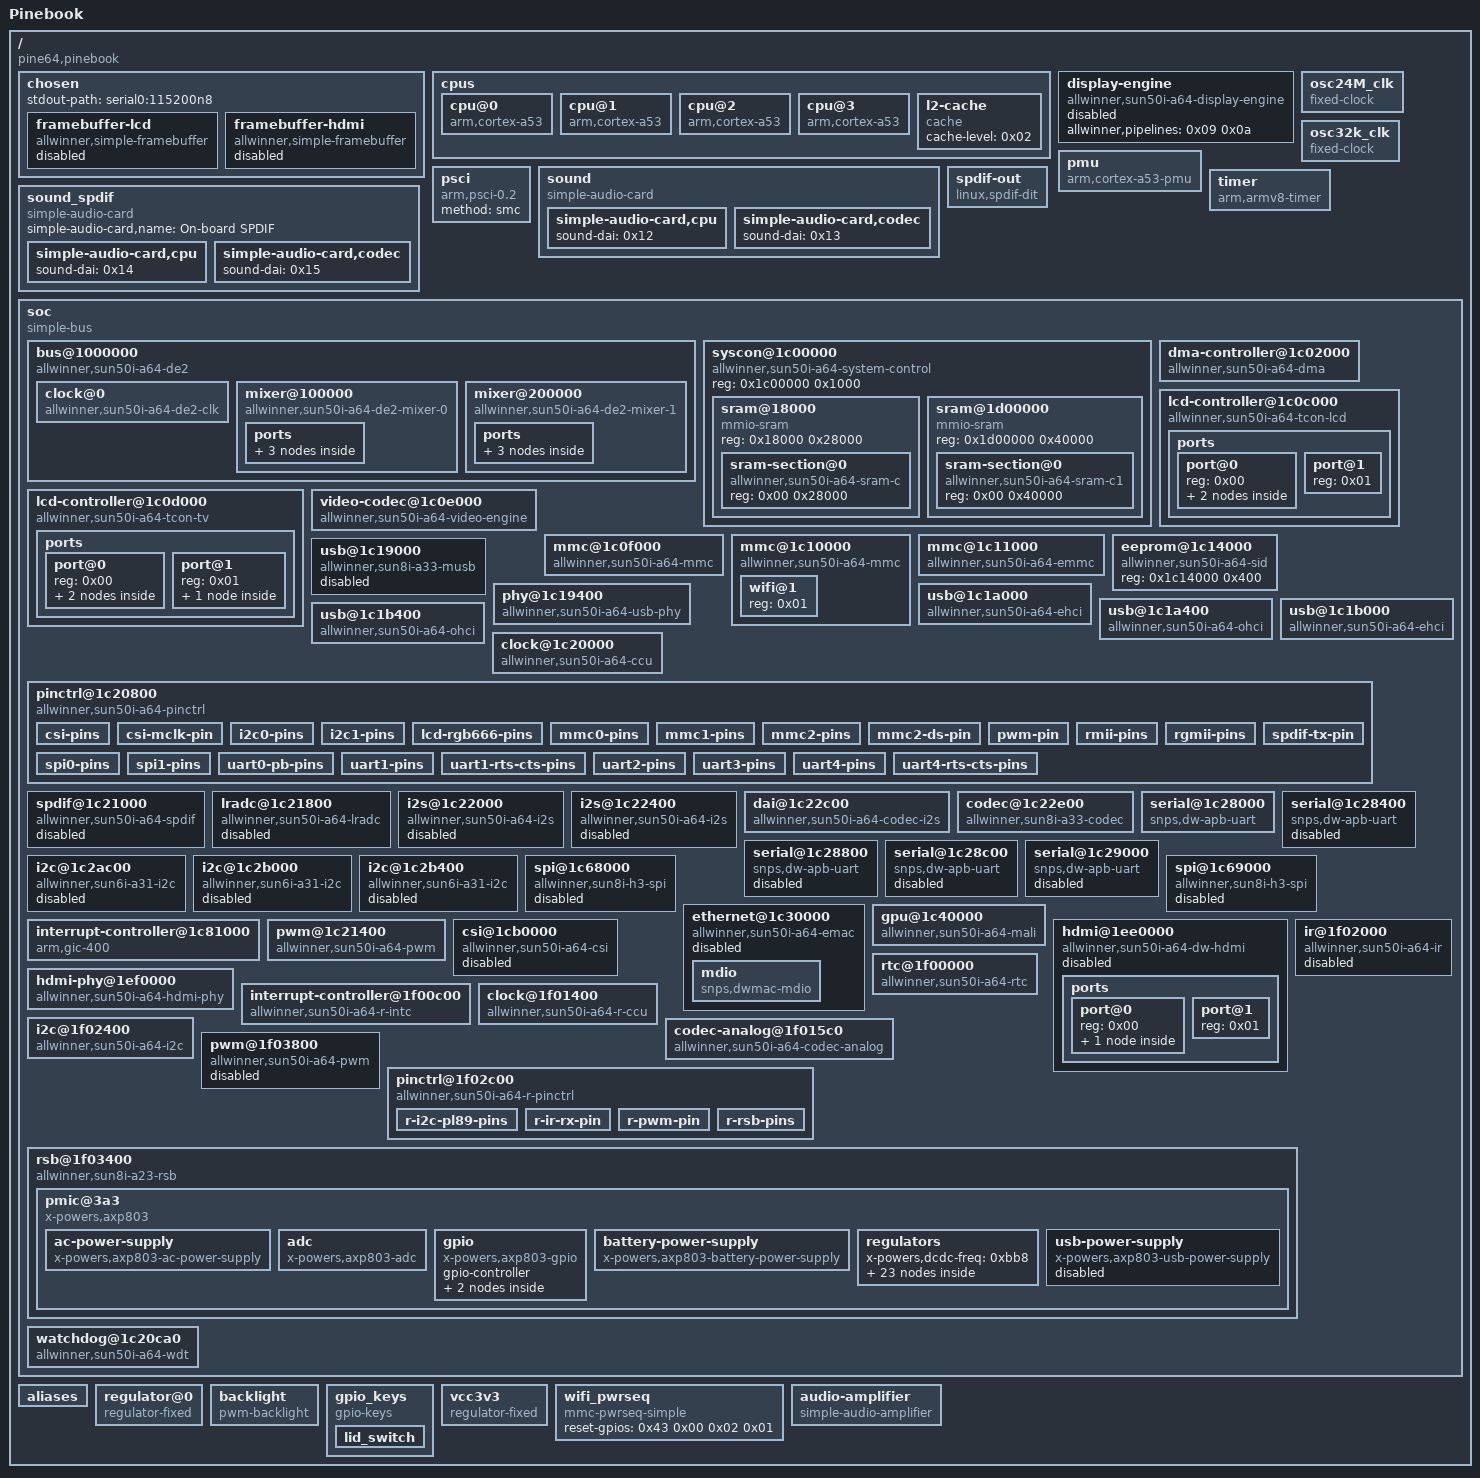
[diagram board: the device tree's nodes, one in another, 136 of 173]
/dts-v1/;

/ {
	interrupt-parent = <0x01>;
	#address-cells = <0x01>;
	#size-cells = <0x01>;
	model = "Pinebook";
	compatible = "pine64,pinebook\0allwinner,sun50i-a64";

	chosen {
		#address-cells = <0x01>;
		#size-cells = <0x01>;
		ranges;
		stdout-path = "serial0:115200n8";

		framebuffer-lcd {
			compatible = "allwinner,simple-framebuffer\0simple-framebuffer";
			allwinner,pipeline = "mixer0-lcd0";
			clocks = <0x02 0x64 0x03 0x06>;
			status = "disabled";
			panel-supply = <0x04>;
			dvdd25-supply = <0x05>;
			dvdd12-supply = <0x06>;
			phandle = <0x44>;
		};

		framebuffer-hdmi {
			compatible = "allwinner,simple-framebuffer\0simple-framebuffer";
			allwinner,pipeline = "mixer1-lcd1-hdmi";
			clocks = <0x03 0x07 0x02 0x65 0x02 0x6e>;
			status = "disabled";
			vcc-hdmi-supply = <0x07>;
			phandle = <0x45>;
		};
	};

	cpus {
		#address-cells = <0x01>;
		#size-cells = <0x00>;

		cpu@0 {
			compatible = "arm,cortex-a53";
			device_type = "cpu";
			reg = <0x00>;
			enable-method = "psci";
			next-level-cache = <0x08>;
			phandle = <0x0b>;
		};

		cpu@1 {
			compatible = "arm,cortex-a53";
			device_type = "cpu";
			reg = <0x01>;
			enable-method = "psci";
			next-level-cache = <0x08>;
			phandle = <0x0c>;
		};

		cpu@2 {
			compatible = "arm,cortex-a53";
			device_type = "cpu";
			reg = <0x02>;
			enable-method = "psci";
			next-level-cache = <0x08>;
			phandle = <0x0d>;
		};

		cpu@3 {
			compatible = "arm,cortex-a53";
			device_type = "cpu";
			reg = <0x03>;
			enable-method = "psci";
			next-level-cache = <0x08>;
			phandle = <0x0e>;
		};

		l2-cache {
			compatible = "cache";
			cache-level = <0x02>;
			phandle = <0x08>;
		};
	};

	display-engine {
		compatible = "allwinner,sun50i-a64-display-engine";
		allwinner,pipelines = <0x09 0x0a>;
		status = "disabled";
		phandle = <0x46>;
	};

	osc24M_clk {
		#clock-cells = <0x00>;
		compatible = "fixed-clock";
		clock-frequency = <0x16e3600>;
		clock-output-names = "osc24M";
		phandle = <0x2c>;
	};

	osc32k_clk {
		#clock-cells = <0x00>;
		compatible = "fixed-clock";
		clock-frequency = <0x8000>;
		clock-output-names = "ext-osc32k";
		phandle = <0x3a>;
	};

	pmu {
		compatible = "arm,cortex-a53-pmu";
		interrupts = <0x00 0x74 0x04 0x00 0x75 0x04 0x00 0x76 0x04 0x00 0x77 0x04>;
		interrupt-affinity = <0x0b 0x0c 0x0d 0x0e>;
	};

	psci {
		compatible = "arm,psci-0.2";
		method = "smc";
	};

	sound {
		compatible = "simple-audio-card";
		simple-audio-card,name = "sun50i-a64-audio";
		simple-audio-card,format = "i2s";
		simple-audio-card,frame-master = <0x0f>;
		simple-audio-card,bitclock-master = <0x0f>;
		simple-audio-card,mclk-fs = <0x80>;
		simple-audio-card,aux-devs = <0x10 0x11>;
		simple-audio-card,routing = "Left DAC\0AIF1 Slot 0 Left\0Right DAC\0AIF1 Slot 0 Right\0Speaker Amp INL\0LINEOUT\0Speaker Amp INR\0LINEOUT\0Internal Speaker\0Speaker Amp OUTL\0Internal Speaker\0Speaker Amp OUTR\0Headphone Jack\0HP\0AIF1 Slot 0 Left ADC\0Left ADC\0AIF1 Slot 0 Right ADC\0Right ADC\0Internal Microphone Left\0MBIAS\0MIC1\0Internal Microphone Left\0Internal Microphone Right\0HBIAS\0MIC2\0Internal Microphone Right";
		status = "okay";
		simple-audio-card,widgets = "Microphone\0Internal Microphone Left\0Microphone\0Internal Microphone Right\0Headphone\0Headphone Jack\0Speaker\0Internal Speaker";
		phandle = <0x47>;

		simple-audio-card,cpu {
			sound-dai = <0x12>;
			phandle = <0x0f>;
		};

		simple-audio-card,codec {
			sound-dai = <0x13>;
			phandle = <0x48>;
		};
	};

	sound_spdif {
		compatible = "simple-audio-card";
		simple-audio-card,name = "On-board SPDIF";

		simple-audio-card,cpu {
			sound-dai = <0x14>;
		};

		simple-audio-card,codec {
			sound-dai = <0x15>;
		};
	};

	spdif-out {
		#sound-dai-cells = <0x00>;
		compatible = "linux,spdif-dit";
		phandle = <0x15>;
	};

	timer {
		compatible = "arm,armv8-timer";
		allwinner,erratum-unknown1;
		interrupts = <0x01 0x0d 0xf04 0x01 0x0e 0xf04 0x01 0x0b 0xf04 0x01 0x0a 0xf04>;
	};

	soc {
		compatible = "simple-bus";
		#address-cells = <0x01>;
		#size-cells = <0x01>;
		ranges;

		bus@1000000 {
			compatible = "allwinner,sun50i-a64-de2";
			reg = <0x1000000 0x400000>;
			allwinner,sram = <0x16 0x01>;
			#address-cells = <0x01>;
			#size-cells = <0x01>;
			ranges = <0x00 0x1000000 0x400000>;

			clock@0 {
				compatible = "allwinner,sun50i-a64-de2-clk";
				reg = <0x00 0x10000>;
				clocks = <0x02 0x34 0x02 0x63>;
				clock-names = "bus\0mod";
				resets = <0x02 0x1e>;
				#clock-cells = <0x01>;
				#reset-cells = <0x01>;
				phandle = <0x03>;
			};

			mixer@100000 {
				compatible = "allwinner,sun50i-a64-de2-mixer-0";
				reg = <0x100000 0x100000>;
				clocks = <0x03 0x00 0x03 0x06>;
				clock-names = "bus\0mod";
				resets = <0x03 0x00>;
				phandle = <0x09>;

				ports {
					#address-cells = <0x01>;
					#size-cells = <0x00>;

					port@1 {
						#address-cells = <0x01>;
						#size-cells = <0x00>;
						reg = <0x01>;
						phandle = <0x49>;

						endpoint@0 {
							reg = <0x00>;
							remote-endpoint = <0x17>;
							phandle = <0x1b>;
						};

						endpoint@1 {
							reg = <0x01>;
							remote-endpoint = <0x18>;
							phandle = <0x1d>;
						};
					};
				};
			};

			mixer@200000 {
				compatible = "allwinner,sun50i-a64-de2-mixer-1";
				reg = <0x200000 0x100000>;
				clocks = <0x03 0x01 0x03 0x07>;
				clock-names = "bus\0mod";
				resets = <0x03 0x01>;
				phandle = <0x0a>;

				ports {
					#address-cells = <0x01>;
					#size-cells = <0x00>;

					port@1 {
						#address-cells = <0x01>;
						#size-cells = <0x00>;
						reg = <0x01>;
						phandle = <0x4a>;

						endpoint@0 {
							reg = <0x00>;
							remote-endpoint = <0x19>;
							phandle = <0x1c>;
						};

						endpoint@1 {
							reg = <0x01>;
							remote-endpoint = <0x1a>;
							phandle = <0x1e>;
						};
					};
				};
			};
		};

		syscon@1c00000 {
			compatible = "allwinner,sun50i-a64-system-control";
			reg = <0x1c00000 0x1000>;
			#address-cells = <0x01>;
			#size-cells = <0x01>;
			ranges;
			phandle = <0x35>;

			sram@18000 {
				compatible = "mmio-sram";
				reg = <0x18000 0x28000>;
				#address-cells = <0x01>;
				#size-cells = <0x01>;
				ranges = <0x00 0x18000 0x28000>;
				phandle = <0x4b>;

				sram-section@0 {
					compatible = "allwinner,sun50i-a64-sram-c";
					reg = <0x00 0x28000>;
					phandle = <0x16>;
				};
			};

			sram@1d00000 {
				compatible = "mmio-sram";
				reg = <0x1d00000 0x40000>;
				#address-cells = <0x01>;
				#size-cells = <0x01>;
				ranges = <0x00 0x1d00000 0x40000>;
				phandle = <0x4c>;

				sram-section@0 {
					compatible = "allwinner,sun50i-a64-sram-c1\0allwinner,sun4i-a10-sram-c1";
					reg = <0x00 0x40000>;
					phandle = <0x20>;
				};
			};
		};

		dma-controller@1c02000 {
			compatible = "allwinner,sun50i-a64-dma";
			reg = <0x1c02000 0x1000>;
			interrupts = <0x00 0x32 0x04>;
			clocks = <0x02 0x1e>;
			dma-channels = <0x08>;
			dma-requests = <0x1b>;
			resets = <0x02 0x07>;
			#dma-cells = <0x01>;
			phandle = <0x2e>;
		};

		lcd-controller@1c0c000 {
			compatible = "allwinner,sun50i-a64-tcon-lcd\0allwinner,sun8i-a83t-tcon-lcd";
			reg = <0x1c0c000 0x1000>;
			interrupts = <0x00 0x56 0x04>;
			clocks = <0x02 0x2f 0x02 0x64>;
			clock-names = "ahb\0tcon-ch0";
			clock-output-names = "tcon-pixel-clock";
			#clock-cells = <0x00>;
			resets = <0x02 0x18 0x02 0x23>;
			reset-names = "lcd\0lvds";
			phandle = <0x4d>;

			ports {
				#address-cells = <0x01>;
				#size-cells = <0x00>;

				port@0 {
					#address-cells = <0x01>;
					#size-cells = <0x00>;
					reg = <0x00>;
					phandle = <0x4e>;

					endpoint@0 {
						reg = <0x00>;
						remote-endpoint = <0x1b>;
						phandle = <0x17>;
					};

					endpoint@1 {
						reg = <0x01>;
						remote-endpoint = <0x1c>;
						phandle = <0x19>;
					};
				};

				port@1 {
					#address-cells = <0x01>;
					#size-cells = <0x00>;
					reg = <0x01>;
					phandle = <0x4f>;
				};
			};
		};

		lcd-controller@1c0d000 {
			compatible = "allwinner,sun50i-a64-tcon-tv\0allwinner,sun8i-a83t-tcon-tv";
			reg = <0x1c0d000 0x1000>;
			interrupts = <0x00 0x57 0x04>;
			clocks = <0x02 0x30 0x02 0x65>;
			clock-names = "ahb\0tcon-ch1";
			resets = <0x02 0x19>;
			reset-names = "lcd";
			phandle = <0x50>;

			ports {
				#address-cells = <0x01>;
				#size-cells = <0x00>;

				port@0 {
					#address-cells = <0x01>;
					#size-cells = <0x00>;
					reg = <0x00>;
					phandle = <0x51>;

					endpoint@0 {
						reg = <0x00>;
						remote-endpoint = <0x1d>;
						phandle = <0x18>;
					};

					endpoint@1 {
						reg = <0x01>;
						remote-endpoint = <0x1e>;
						phandle = <0x1a>;
					};
				};

				port@1 {
					#address-cells = <0x01>;
					#size-cells = <0x00>;
					reg = <0x01>;
					phandle = <0x52>;

					endpoint@1 {
						reg = <0x01>;
						remote-endpoint = <0x1f>;
						phandle = <0x39>;
					};
				};
			};
		};

		video-codec@1c0e000 {
			compatible = "allwinner,sun50i-a64-video-engine";
			reg = <0x1c0e000 0x1000>;
			clocks = <0x02 0x2e 0x02 0x6a 0x02 0x5f>;
			clock-names = "ahb\0mod\0ram";
			resets = <0x02 0x17>;
			interrupts = <0x00 0x3a 0x04>;
			allwinner,sram = <0x20 0x01>;
		};

		mmc@1c0f000 {
			compatible = "allwinner,sun50i-a64-mmc";
			reg = <0x1c0f000 0x1000>;
			clocks = <0x02 0x1f 0x02 0x4b>;
			clock-names = "ahb\0mmc";
			resets = <0x02 0x08>;
			reset-names = "ahb";
			interrupts = <0x00 0x3c 0x04>;
			max-frequency = <0x8f0d180>;
			status = "okay";
			#address-cells = <0x01>;
			#size-cells = <0x00>;
			pinctrl-names = "default";
			pinctrl-0 = <0x21>;
			vmmc-supply = <0x22>;
			cd-gpios = <0x23 0x05 0x06 0x01>;
			disable-wp;
			bus-width = <0x04>;
			phandle = <0x53>;
		};

		mmc@1c10000 {
			compatible = "allwinner,sun50i-a64-mmc";
			reg = <0x1c10000 0x1000>;
			clocks = <0x02 0x20 0x02 0x4c>;
			clock-names = "ahb\0mmc";
			resets = <0x02 0x09>;
			reset-names = "ahb";
			interrupts = <0x00 0x3d 0x04>;
			max-frequency = <0x8f0d180>;
			status = "okay";
			#address-cells = <0x01>;
			#size-cells = <0x00>;
			pinctrl-names = "default";
			pinctrl-0 = <0x24>;
			vmmc-supply = <0x25>;
			vqmmc-supply = <0x26>;
			mmc-pwrseq = <0x27>;
			bus-width = <0x04>;
			non-removable;
			phandle = <0x54>;

			wifi@1 {
				reg = <0x01>;
				phandle = <0x55>;
			};
		};

		mmc@1c11000 {
			compatible = "allwinner,sun50i-a64-emmc";
			reg = <0x1c11000 0x1000>;
			clocks = <0x02 0x21 0x02 0x4d>;
			clock-names = "ahb\0mmc";
			resets = <0x02 0x0a>;
			reset-names = "ahb";
			interrupts = <0x00 0x3e 0x04>;
			max-frequency = <0xbebc200>;
			status = "okay";
			#address-cells = <0x01>;
			#size-cells = <0x00>;
			pinctrl-names = "default";
			pinctrl-0 = <0x28 0x29>;
			vmmc-supply = <0x22>;
			vqmmc-supply = <0x26>;
			bus-width = <0x08>;
			non-removable;
			cap-mmc-hw-reset;
			mmc-hs200-1_8v;
			phandle = <0x56>;
		};

		eeprom@1c14000 {
			compatible = "allwinner,sun50i-a64-sid";
			reg = <0x1c14000 0x400>;
			phandle = <0x57>;
		};

		usb@1c19000 {
			compatible = "allwinner,sun8i-a33-musb";
			reg = <0x1c19000 0x400>;
			clocks = <0x02 0x29>;
			resets = <0x02 0x12>;
			interrupts = <0x00 0x47 0x04>;
			interrupt-names = "mc";
			phys = <0x2a 0x00>;
			phy-names = "usb";
			extcon = <0x2a 0x00>;
			dr_mode = "host";
			status = "disabled";
			phandle = <0x58>;
		};

		phy@1c19400 {
			compatible = "allwinner,sun50i-a64-usb-phy";
			reg = <0x1c19400 0x14 0x1c1a800 0x04 0x1c1b800 0x04>;
			reg-names = "phy_ctrl\0pmu0\0pmu1";
			clocks = <0x02 0x56 0x02 0x57>;
			clock-names = "usb0_phy\0usb1_phy";
			resets = <0x02 0x00 0x02 0x01>;
			reset-names = "usb0_reset\0usb1_reset";
			status = "okay";
			#phy-cells = <0x01>;
			usb0_vbus-supply = <0x2b>;
			usb1_vbus-supply = <0x2b>;
			phandle = <0x2a>;
		};

		usb@1c1a000 {
			compatible = "allwinner,sun50i-a64-ehci\0generic-ehci";
			reg = <0x1c1a000 0x100>;
			interrupts = <0x00 0x48 0x04>;
			clocks = <0x02 0x2c 0x02 0x2a 0x02 0x5b>;
			resets = <0x02 0x15 0x02 0x13>;
			phys = <0x2a 0x00>;
			phy-names = "usb";
			status = "okay";
			phandle = <0x59>;
		};

		usb@1c1a400 {
			compatible = "allwinner,sun50i-a64-ohci\0generic-ohci";
			reg = <0x1c1a400 0x100>;
			interrupts = <0x00 0x49 0x04>;
			clocks = <0x02 0x2c 0x02 0x5b>;
			resets = <0x02 0x15>;
			phys = <0x2a 0x00>;
			phy-names = "usb";
			status = "okay";
			phandle = <0x5a>;
		};

		usb@1c1b000 {
			compatible = "allwinner,sun50i-a64-ehci\0generic-ehci";
			reg = <0x1c1b000 0x100>;
			interrupts = <0x00 0x4a 0x04>;
			clocks = <0x02 0x2d 0x02 0x2b 0x02 0x5d>;
			resets = <0x02 0x16 0x02 0x14>;
			phys = <0x2a 0x01>;
			phy-names = "usb";
			status = "okay";
			phandle = <0x5b>;
		};

		usb@1c1b400 {
			compatible = "allwinner,sun50i-a64-ohci\0generic-ohci";
			reg = <0x1c1b400 0x100>;
			interrupts = <0x00 0x4b 0x04>;
			clocks = <0x02 0x2d 0x02 0x5d>;
			resets = <0x02 0x16>;
			phys = <0x2a 0x01>;
			phy-names = "usb";
			status = "okay";
			phandle = <0x5c>;
		};

		clock@1c20000 {
			compatible = "allwinner,sun50i-a64-ccu";
			reg = <0x1c20000 0x400>;
			clocks = <0x2c 0x2d 0x00>;
			clock-names = "hosc\0losc";
			#clock-cells = <0x01>;
			#reset-cells = <0x01>;
			phandle = <0x02>;
		};

		pinctrl@1c20800 {
			compatible = "allwinner,sun50i-a64-pinctrl";
			reg = <0x1c20800 0x400>;
			interrupts = <0x00 0x0b 0x04 0x00 0x11 0x04 0x00 0x15 0x04>;
			clocks = <0x02 0x3a 0x2c 0x2d 0x00>;
			clock-names = "apb\0hosc\0losc";
			gpio-controller;
			#gpio-cells = <0x03>;
			interrupt-controller;
			#interrupt-cells = <0x03>;
			phandle = <0x23>;

			csi-pins {
				pins = "PE0\0PE2\0PE3\0PE4\0PE5\0PE6\0PE7\0PE8\0PE9\0PE10\0PE11";
				function = "csi";
				phandle = <0x37>;
			};

			csi-mclk-pin {
				pins = "PE1";
				function = "csi";
				phandle = <0x5d>;
			};

			i2c0-pins {
				pins = "PH0\0PH1";
				function = "i2c0";
				phandle = <0x31>;
			};

			i2c1-pins {
				pins = "PH2\0PH3";
				function = "i2c1";
				phandle = <0x32>;
			};

			lcd-rgb666-pins {
				pins = "PD0\0PD1\0PD2\0PD3\0PD4\0PD5\0PD6\0PD7\0PD8\0PD9\0PD10\0PD11\0PD12\0PD13\0PD14\0PD15\0PD16\0PD17\0PD18\0PD19\0PD20\0PD21";
				function = "lcd0";
				phandle = <0x5e>;
			};

			mmc0-pins {
				pins = "PF0\0PF1\0PF2\0PF3\0PF4\0PF5";
				function = "mmc0";
				drive-strength = <0x1e>;
				bias-pull-up;
				phandle = <0x21>;
			};

			mmc1-pins {
				pins = "PG0\0PG1\0PG2\0PG3\0PG4\0PG5";
				function = "mmc1";
				drive-strength = <0x1e>;
				bias-pull-up;
				phandle = <0x24>;
			};

			mmc2-pins {
				pins = "PC5\0PC6\0PC8\0PC9\0PC10\0PC11\0PC12\0PC13\0PC14\0PC15\0PC16";
				function = "mmc2";
				drive-strength = <0x1e>;
				bias-pull-up;
				phandle = <0x28>;
			};

			mmc2-ds-pin {
				pins = "PC1";
				function = "mmc2";
				drive-strength = <0x1e>;
				bias-pull-up;
				phandle = <0x29>;
			};

			pwm-pin {
				pins = "PD22";
				function = "pwm";
				phandle = <0x36>;
			};

			rmii-pins {
				pins = "PD10\0PD11\0PD13\0PD14\0PD17\0PD18\0PD19\0PD20\0PD22\0PD23";
				function = "emac";
				drive-strength = <0x28>;
				phandle = <0x5f>;
			};

			rgmii-pins {
				pins = "PD8\0PD9\0PD10\0PD11\0PD12\0PD13\0PD15\0PD16\0PD17\0PD18\0PD19\0PD20\0PD21\0PD22\0PD23";
				function = "emac";
				drive-strength = <0x28>;
				phandle = <0x60>;
			};

			spdif-tx-pin {
				pins = "PH8";
				function = "spdif";
				phandle = <0x2f>;
			};

			spi0-pins {
				pins = "PC0\0PC1\0PC2\0PC3";
				function = "spi0";
				phandle = <0x33>;
			};

			spi1-pins {
				pins = "PD0\0PD1\0PD2\0PD3";
				function = "spi1";
				phandle = <0x34>;
			};

			uart0-pb-pins {
				pins = "PB8\0PB9";
				function = "uart0";
				phandle = <0x30>;
			};

			uart1-pins {
				pins = "PG6\0PG7";
				function = "uart1";
				phandle = <0x61>;
			};

			uart1-rts-cts-pins {
				pins = "PG8\0PG9";
				function = "uart1";
				phandle = <0x62>;
			};

			uart2-pins {
				pins = "PB0\0PB1";
				function = "uart2";
				phandle = <0x63>;
			};

			uart3-pins {
				pins = "PD0\0PD1";
				function = "uart3";
				phandle = <0x64>;
			};

			uart4-pins {
				pins = "PD2\0PD3";
				function = "uart4";
				phandle = <0x65>;
			};

			uart4-rts-cts-pins {
				pins = "PD4\0PD5";
				function = "uart4";
				phandle = <0x66>;
			};
		};

		spdif@1c21000 {
			#sound-dai-cells = <0x00>;
			compatible = "allwinner,sun50i-a64-spdif\0allwinner,sun8i-h3-spdif";
			reg = <0x1c21000 0x400>;
			interrupts = <0x00 0x0c 0x04>;
			clocks = <0x02 0x39 0x02 0x55>;
			resets = <0x02 0x25>;
			clock-names = "apb\0spdif";
			dmas = <0x2e 0x02>;
			dma-names = "tx";
			pinctrl-names = "default";
			pinctrl-0 = <0x2f>;
			status = "disabled";
			phandle = <0x14>;
		};

		lradc@1c21800 {
			compatible = "allwinner,sun50i-a64-lradc\0allwinner,sun8i-a83t-r-lradc";
			reg = <0x1c21800 0x400>;
			interrupts = <0x00 0x1e 0x04>;
			status = "disabled";
			phandle = <0x67>;
		};

		i2s@1c22000 {
			#sound-dai-cells = <0x00>;
			compatible = "allwinner,sun50i-a64-i2s\0allwinner,sun8i-h3-i2s";
			reg = <0x1c22000 0x400>;
			interrupts = <0x00 0x0d 0x04>;
			clocks = <0x02 0x3c 0x02 0x52>;
			clock-names = "apb\0mod";
			resets = <0x02 0x27>;
			dma-names = "rx\0tx";
			dmas = <0x2e 0x03 0x2e 0x03>;
			status = "disabled";
			phandle = <0x68>;
		};

		i2s@1c22400 {
			#sound-dai-cells = <0x00>;
			compatible = "allwinner,sun50i-a64-i2s\0allwinner,sun8i-h3-i2s";
			reg = <0x1c22400 0x400>;
			interrupts = <0x00 0x0e 0x04>;
			clocks = <0x02 0x3d 0x02 0x53>;
			clock-names = "apb\0mod";
			resets = <0x02 0x28>;
			dma-names = "rx\0tx";
			dmas = <0x2e 0x04 0x2e 0x04>;
			status = "disabled";
			phandle = <0x69>;
		};

		dai@1c22c00 {
			#sound-dai-cells = <0x00>;
			compatible = "allwinner,sun50i-a64-codec-i2s";
			reg = <0x1c22c00 0x200>;
			interrupts = <0x00 0x1d 0x04>;
			clocks = <0x02 0x38 0x02 0x6b>;
			clock-names = "apb\0mod";
			resets = <0x02 0x24>;
			dmas = <0x2e 0x0f 0x2e 0x0f>;
			dma-names = "rx\0tx";
			status = "okay";
			phandle = <0x12>;
		};

		codec@1c22e00 {
			#sound-dai-cells = <0x00>;
			compatible = "allwinner,sun8i-a33-codec";
			reg = <0x1c22e00 0x600>;
			interrupts = <0x00 0x1c 0x04>;
			clocks = <0x02 0x38 0x02 0x6b>;
			clock-names = "bus\0mod";
			status = "okay";
			phandle = <0x13>;
		};

		serial@1c28000 {
			compatible = "snps,dw-apb-uart";
			reg = <0x1c28000 0x400>;
			interrupts = <0x00 0x00 0x04>;
			reg-shift = <0x02>;
			reg-io-width = <0x04>;
			clocks = <0x02 0x43>;
			resets = <0x02 0x2e>;
			status = "okay";
			pinctrl-names = "default";
			pinctrl-0 = <0x30>;
			phandle = <0x6a>;
		};

		serial@1c28400 {
			compatible = "snps,dw-apb-uart";
			reg = <0x1c28400 0x400>;
			interrupts = <0x00 0x01 0x04>;
			reg-shift = <0x02>;
			reg-io-width = <0x04>;
			clocks = <0x02 0x44>;
			resets = <0x02 0x2f>;
			status = "disabled";
			phandle = <0x6b>;
		};

		serial@1c28800 {
			compatible = "snps,dw-apb-uart";
			reg = <0x1c28800 0x400>;
			interrupts = <0x00 0x02 0x04>;
			reg-shift = <0x02>;
			reg-io-width = <0x04>;
			clocks = <0x02 0x45>;
			resets = <0x02 0x30>;
			status = "disabled";
			phandle = <0x6c>;
		};

		serial@1c28c00 {
			compatible = "snps,dw-apb-uart";
			reg = <0x1c28c00 0x400>;
			interrupts = <0x00 0x03 0x04>;
			reg-shift = <0x02>;
			reg-io-width = <0x04>;
			clocks = <0x02 0x46>;
			resets = <0x02 0x31>;
			status = "disabled";
			phandle = <0x6d>;
		};

		serial@1c29000 {
			compatible = "snps,dw-apb-uart";
			reg = <0x1c29000 0x400>;
			interrupts = <0x00 0x04 0x04>;
			reg-shift = <0x02>;
			reg-io-width = <0x04>;
			clocks = <0x02 0x47>;
			resets = <0x02 0x32>;
			status = "disabled";
			phandle = <0x6e>;
		};

		i2c@1c2ac00 {
			compatible = "allwinner,sun6i-a31-i2c";
			reg = <0x1c2ac00 0x400>;
			interrupts = <0x00 0x06 0x04>;
			clocks = <0x02 0x3f>;
			resets = <0x02 0x2a>;
			pinctrl-names = "default";
			pinctrl-0 = <0x31>;
			status = "disabled";
			#address-cells = <0x01>;
			#size-cells = <0x00>;
			phandle = <0x6f>;
		};

		i2c@1c2b000 {
			compatible = "allwinner,sun6i-a31-i2c";
			reg = <0x1c2b000 0x400>;
			interrupts = <0x00 0x07 0x04>;
			clocks = <0x02 0x40>;
			resets = <0x02 0x2b>;
			pinctrl-names = "default";
			pinctrl-0 = <0x32>;
			status = "disabled";
			#address-cells = <0x01>;
			#size-cells = <0x00>;
			phandle = <0x70>;
		};

		i2c@1c2b400 {
			compatible = "allwinner,sun6i-a31-i2c";
			reg = <0x1c2b400 0x400>;
			interrupts = <0x00 0x08 0x04>;
			clocks = <0x02 0x41>;
			resets = <0x02 0x2c>;
			status = "disabled";
			#address-cells = <0x01>;
			#size-cells = <0x00>;
			phandle = <0x71>;
		};

		spi@1c68000 {
			compatible = "allwinner,sun8i-h3-spi";
			reg = <0x1c68000 0x1000>;
			interrupts = <0x00 0x41 0x04>;
			clocks = <0x02 0x27 0x02 0x50>;
			clock-names = "ahb\0mod";
			dmas = <0x2e 0x17 0x2e 0x17>;
			dma-names = "rx\0tx";
			pinctrl-names = "default";
			pinctrl-0 = <0x33>;
			resets = <0x02 0x10>;
			status = "disabled";
			num-cs = <0x01>;
			#address-cells = <0x01>;
			#size-cells = <0x00>;
			phandle = <0x72>;
		};

		spi@1c69000 {
			compatible = "allwinner,sun8i-h3-spi";
			reg = <0x1c69000 0x1000>;
			interrupts = <0x00 0x42 0x04>;
			clocks = <0x02 0x28 0x02 0x51>;
			clock-names = "ahb\0mod";
			dmas = <0x2e 0x18 0x2e 0x18>;
			dma-names = "rx\0tx";
			pinctrl-names = "default";
			pinctrl-0 = <0x34>;
			resets = <0x02 0x11>;
			status = "disabled";
			num-cs = <0x01>;
			#address-cells = <0x01>;
			#size-cells = <0x00>;
			phandle = <0x73>;
		};

		ethernet@1c30000 {
			compatible = "allwinner,sun50i-a64-emac";
			syscon = <0x35>;
			reg = <0x1c30000 0x10000>;
			interrupts = <0x00 0x52 0x04>;
			interrupt-names = "macirq";
			resets = <0x02 0x0d>;
			reset-names = "stmmaceth";
			clocks = <0x02 0x24>;
			clock-names = "stmmaceth";
			status = "disabled";
			phandle = <0x74>;

			mdio {
				compatible = "snps,dwmac-mdio";
				#address-cells = <0x01>;
				#size-cells = <0x00>;
				phandle = <0x75>;
			};
		};

		gpu@1c40000 {
			compatible = "allwinner,sun50i-a64-mali\0arm,mali-400";
			reg = <0x1c40000 0x10000>;
			interrupts = <0x00 0x61 0x04 0x00 0x62 0x04 0x00 0x63 0x04 0x00 0x64 0x04 0x00 0x66 0x04 0x00 0x67 0x04 0x00 0x65 0x04>;
			interrupt-names = "gp\0gpmmu\0pp0\0ppmmu0\0pp1\0ppmmu1\0pmu";
			clocks = <0x02 0x35 0x02 0x72>;
			clock-names = "bus\0core";
			resets = <0x02 0x1f>;
			phandle = <0x76>;
		};

		interrupt-controller@1c81000 {
			compatible = "arm,gic-400";
			reg = <0x1c81000 0x1000 0x1c82000 0x2000 0x1c84000 0x2000 0x1c86000 0x2000>;
			interrupts = <0x01 0x09 0xf04>;
			interrupt-controller;
			#interrupt-cells = <0x03>;
			phandle = <0x01>;
		};

		pwm@1c21400 {
			compatible = "allwinner,sun50i-a64-pwm\0allwinner,sun5i-a13-pwm";
			reg = <0x1c21400 0x400>;
			clocks = <0x2c>;
			pinctrl-names = "default";
			pinctrl-0 = <0x36>;
			#pwm-cells = <0x03>;
			status = "okay";
			phandle = <0x41>;
		};

		csi@1cb0000 {
			compatible = "allwinner,sun50i-a64-csi";
			reg = <0x1cb0000 0x1000>;
			interrupts = <0x00 0x54 0x04>;
			clocks = <0x02 0x32 0x02 0x68 0x02 0x60>;
			clock-names = "bus\0mod\0ram";
			resets = <0x02 0x1b>;
			pinctrl-names = "default";
			pinctrl-0 = <0x37>;
			status = "disabled";
			phandle = <0x77>;
		};

		hdmi@1ee0000 {
			compatible = "allwinner,sun50i-a64-dw-hdmi\0allwinner,sun8i-a83t-dw-hdmi";
			reg = <0x1ee0000 0x10000>;
			reg-io-width = <0x01>;
			interrupts = <0x00 0x58 0x04>;
			clocks = <0x02 0x33 0x02 0x6f 0x02 0x6e>;
			clock-names = "iahb\0isfr\0tmds";
			resets = <0x02 0x1d>;
			reset-names = "ctrl";
			phys = <0x38>;
			phy-names = "phy";
			status = "disabled";
			phandle = <0x78>;

			ports {
				#address-cells = <0x01>;
				#size-cells = <0x00>;

				port@0 {
					reg = <0x00>;
					phandle = <0x79>;

					endpoint {
						remote-endpoint = <0x39>;
						phandle = <0x1f>;
					};
				};

				port@1 {
					reg = <0x01>;
					phandle = <0x7a>;
				};
			};
		};

		hdmi-phy@1ef0000 {
			compatible = "allwinner,sun50i-a64-hdmi-phy";
			reg = <0x1ef0000 0x10000>;
			clocks = <0x02 0x33 0x02 0x6f 0x02 0x07>;
			clock-names = "bus\0mod\0pll-0";
			resets = <0x02 0x1c>;
			reset-names = "phy";
			#phy-cells = <0x00>;
			phandle = <0x38>;
		};

		rtc@1f00000 {
			compatible = "allwinner,sun50i-a64-rtc\0allwinner,sun8i-h3-rtc";
			reg = <0x1f00000 0x400>;
			interrupts = <0x00 0x28 0x04 0x00 0x29 0x04>;
			clock-output-names = "osc32k\0osc32k-out\0iosc";
			clocks = <0x3a>;
			#clock-cells = <0x01>;
			phandle = <0x2d>;
		};

		interrupt-controller@1f00c00 {
			compatible = "allwinner,sun50i-a64-r-intc\0allwinner,sun6i-a31-r-intc";
			interrupt-controller;
			#interrupt-cells = <0x02>;
			reg = <0x1f00c00 0x400>;
			interrupts = <0x00 0x20 0x04>;
			phandle = <0x40>;
		};

		clock@1f01400 {
			compatible = "allwinner,sun50i-a64-r-ccu";
			reg = <0x1f01400 0x100>;
			clocks = <0x2c 0x2d 0x00 0x2d 0x02 0x02 0x0b>;
			clock-names = "hosc\0losc\0iosc\0pll-periph";
			#clock-cells = <0x01>;
			#reset-cells = <0x01>;
			phandle = <0x3b>;
		};

		codec-analog@1f015c0 {
			compatible = "allwinner,sun50i-a64-codec-analog";
			reg = <0x1f015c0 0x04>;
			status = "okay";
			cpvdd-supply = <0x26>;
			phandle = <0x10>;
		};

		i2c@1f02400 {
			compatible = "allwinner,sun50i-a64-i2c\0allwinner,sun6i-a31-i2c";
			reg = <0x1f02400 0x400>;
			interrupts = <0x00 0x2c 0x04>;
			clocks = <0x3b 0x09>;
			resets = <0x3b 0x05>;
			status = "okay";
			#address-cells = <0x01>;
			#size-cells = <0x00>;
			clock-frequency = <0x186a0>;
			pinctrl-names = "default";
			pinctrl-0 = <0x3c>;
			phandle = <0x7b>;
		};

		ir@1f02000 {
			compatible = "allwinner,sun50i-a64-ir\0allwinner,sun6i-a31-ir";
			reg = <0x1f02000 0x400>;
			clocks = <0x3b 0x04 0x3b 0x0b>;
			clock-names = "apb\0ir";
			resets = <0x3b 0x00>;
			interrupts = <0x00 0x25 0x04>;
			pinctrl-names = "default";
			pinctrl-0 = <0x3d>;
			status = "disabled";
			phandle = <0x7c>;
		};

		pwm@1f03800 {
			compatible = "allwinner,sun50i-a64-pwm\0allwinner,sun5i-a13-pwm";
			reg = <0x1f03800 0x400>;
			clocks = <0x2c>;
			pinctrl-names = "default";
			pinctrl-0 = <0x3e>;
			#pwm-cells = <0x03>;
			status = "disabled";
			phandle = <0x7d>;
		};

		pinctrl@1f02c00 {
			compatible = "allwinner,sun50i-a64-r-pinctrl";
			reg = <0x1f02c00 0x400>;
			interrupts = <0x00 0x2d 0x04>;
			clocks = <0x3b 0x03 0x2c 0x3a>;
			clock-names = "apb\0hosc\0losc";
			gpio-controller;
			#gpio-cells = <0x03>;
			interrupt-controller;
			#interrupt-cells = <0x03>;
			phandle = <0x43>;

			r-i2c-pl89-pins {
				pins = "PL8\0PL9";
				function = "s_i2c";
				phandle = <0x3c>;
			};

			r-ir-rx-pin {
				pins = "PL11";
				function = "s_cir_rx";
				phandle = <0x3d>;
			};

			r-pwm-pin {
				pins = "PL10";
				function = "s_pwm";
				phandle = <0x3e>;
			};

			r-rsb-pins {
				pins = "PL0\0PL1";
				function = "s_rsb";
				phandle = <0x3f>;
			};
		};

		rsb@1f03400 {
			compatible = "allwinner,sun8i-a23-rsb";
			reg = <0x1f03400 0x400>;
			interrupts = <0x00 0x27 0x04>;
			clocks = <0x3b 0x06>;
			clock-frequency = <0x2dc6c0>;
			resets = <0x3b 0x02>;
			pinctrl-names = "default";
			pinctrl-0 = <0x3f>;
			status = "okay";
			#address-cells = <0x01>;
			#size-cells = <0x00>;
			phandle = <0x7e>;

			pmic@3a3 {
				compatible = "x-powers,axp803";
				reg = <0x3a3>;
				interrupt-parent = <0x40>;
				interrupts = <0x00 0x08>;
				interrupt-controller;
				#interrupt-cells = <0x01>;
				phandle = <0x7f>;

				ac-power-supply {
					compatible = "x-powers,axp803-ac-power-supply\0x-powers,axp813-ac-power-supply";
					status = "okay";
					phandle = <0x80>;
				};

				adc {
					compatible = "x-powers,axp803-adc\0x-powers,axp813-adc";
					#io-channel-cells = <0x01>;
					phandle = <0x81>;
				};

				gpio {
					compatible = "x-powers,axp803-gpio\0x-powers,axp813-gpio";
					gpio-controller;
					#gpio-cells = <0x02>;
					phandle = <0x82>;

					gpio0-ldo {
						pins = "GPIO0";
						function = "ldo";
						phandle = <0x83>;
					};

					gpio1-ldo {
						pins = "GPIO1";
						function = "ldo";
						phandle = <0x84>;
					};
				};

				battery-power-supply {
					compatible = "x-powers,axp803-battery-power-supply\0x-powers,axp813-battery-power-supply";
					status = "okay";
					phandle = <0x85>;
				};

				regulators {
					x-powers,dcdc-freq = <0xbb8>;

					aldo1 {
						regulator-name = "vcc-csi";
						regulator-min-microvolt = <0x2ab980>;
						regulator-max-microvolt = <0x2ab980>;
						phandle = <0x86>;
					};

					aldo2 {
						regulator-name = "vcc-pl";
						regulator-always-on;
						regulator-min-microvolt = <0x1b7740>;
						regulator-max-microvolt = <0x325aa0>;
						phandle = <0x87>;
					};

					aldo3 {
						regulator-name = "vcc-pll-avcc";
						regulator-always-on;
						regulator-min-microvolt = <0x2932e0>;
						regulator-max-microvolt = <0x325aa0>;
						phandle = <0x88>;
					};

					dc1sw {
						regulator-name = "vcc-lcd";
						phandle = <0x04>;
					};

					dcdc1 {
						regulator-name = "vcc-3v3";
						regulator-always-on;
						regulator-min-microvolt = <0x325aa0>;
						regulator-max-microvolt = <0x325aa0>;
						phandle = <0x22>;
					};

					dcdc2 {
						regulator-name = "vdd-cpux";
						regulator-always-on;
						regulator-min-microvolt = <0xf4240>;
						regulator-max-microvolt = <0x13d620>;
						phandle = <0x89>;
					};

					dcdc3 {
						regulator-name = "dcdc3";
						phandle = <0x8a>;
					};

					dcdc4 {
						regulator-name = "dcdc4";
						phandle = <0x8b>;
					};

					dcdc5 {
						regulator-name = "vcc-dram";
						regulator-always-on;
						regulator-min-microvolt = <0x124f80>;
						regulator-max-microvolt = <0x124f80>;
						phandle = <0x8c>;
					};

					dcdc6 {
						regulator-name = "vdd-sys";
						regulator-always-on;
						regulator-min-microvolt = <0x10c8e0>;
						regulator-max-microvolt = <0x10c8e0>;
						phandle = <0x8d>;
					};

					dldo1 {
						regulator-name = "vcc-hdmi";
						regulator-min-microvolt = <0x325aa0>;
						regulator-max-microvolt = <0x325aa0>;
						phandle = <0x07>;
					};

					dldo2 {
						regulator-name = "vcc-edp";
						regulator-min-microvolt = <0x2625a0>;
						regulator-max-microvolt = <0x2625a0>;
						phandle = <0x05>;
					};

					dldo3 {
						regulator-name = "avdd-csi";
						regulator-min-microvolt = <0x325aa0>;
						regulator-max-microvolt = <0x325aa0>;
						phandle = <0x8e>;
					};

					dldo4 {
						regulator-name = "vcc-wifi";
						regulator-min-microvolt = <0x325aa0>;
						regulator-max-microvolt = <0x325aa0>;
						phandle = <0x25>;
					};

					eldo1 {
						regulator-name = "cpvdd";
						regulator-always-on;
						regulator-min-microvolt = <0x1b7740>;
						regulator-max-microvolt = <0x1b7740>;
						phandle = <0x26>;
					};

					eldo2 {
						regulator-name = "eldo2";
						phandle = <0x8f>;
					};

					eldo3 {
						regulator-name = "vdd-1v8-csi";
						regulator-min-microvolt = <0x1b7740>;
						regulator-max-microvolt = <0x1b7740>;
						phandle = <0x90>;
					};

					fldo1 {
						regulator-name = "vcc-1v2-hsic";
						regulator-min-microvolt = <0x124f80>;
						regulator-max-microvolt = <0x124f80>;
						phandle = <0x06>;
					};

					fldo2 {
						regulator-name = "vdd-cpus";
						regulator-always-on;
						regulator-min-microvolt = <0x10c8e0>;
						regulator-max-microvolt = <0x10c8e0>;
						phandle = <0x91>;
					};

					ldo-io0 {
						regulator-name = "vcc-usb";
						status = "okay";
						regulator-min-microvolt = <0x325aa0>;
						regulator-max-microvolt = <0x325aa0>;
						phandle = <0x2b>;
					};

					ldo-io1 {
						regulator-name = "ldo-io1";
						status = "disabled";
						phandle = <0x92>;
					};

					rtc-ldo {
						regulator-always-on;
						regulator-min-microvolt = <0x2dc6c0>;
						regulator-max-microvolt = <0x2dc6c0>;
						regulator-name = "vcc-rtc";
						phandle = <0x93>;
					};

					drivevbus {
						regulator-name = "drivevbus";
						status = "disabled";
						phandle = <0x94>;
					};
				};

				usb-power-supply {
					compatible = "x-powers,axp803-usb-power-supply\0x-powers,axp813-usb-power-supply";
					status = "disabled";
					phandle = <0x95>;
				};
			};
		};

		watchdog@1c20ca0 {
			compatible = "allwinner,sun50i-a64-wdt\0allwinner,sun6i-a31-wdt";
			reg = <0x1c20ca0 0x20>;
			interrupts = <0x00 0x19 0x04>;
			clocks = <0x2c>;
			phandle = <0x96>;
		};
	};

	aliases {
		serial0 = "/soc/serial@1c28000";
		ethernet0 = "/soc/mmc@1c10000/wifi@1";
	};

	regulator@0 {
		compatible = "regulator-fixed";
		regulator-name = "bl-3v3";
		regulator-min-microvolt = <0x325aa0>;
		regulator-max-microvolt = <0x325aa0>;
		gpio = <0x23 0x07 0x06 0x00>;
		enable-active-high;
		phandle = <0x42>;
	};

	backlight {
		compatible = "pwm-backlight";
		pwms = <0x41 0x00 0xc350 0x00>;
		brightness-levels = <0x00 0x05 0x0a 0x0f 0x14 0x1e 0x28 0x37 0x46 0x55 0x64>;
		default-brightness-level = <0x02>;
		enable-gpios = <0x23 0x03 0x17 0x00>;
		power-supply = <0x42>;
		phandle = <0x97>;
	};

	gpio_keys {
		compatible = "gpio-keys";

		lid_switch {
			label = "Lid Switch";
			gpios = <0x43 0x00 0x0c 0x01>;
			linux,input-type = <0x05>;
			linux,code = <0x00>;
			linux,can-disable;
			wakeup-source;
		};
	};

	vcc3v3 {
		compatible = "regulator-fixed";
		regulator-name = "vcc3v3";
		regulator-min-microvolt = <0x325aa0>;
		regulator-max-microvolt = <0x325aa0>;
		phandle = <0x98>;
	};

	wifi_pwrseq {
		compatible = "mmc-pwrseq-simple";
		reset-gpios = <0x43 0x00 0x02 0x01>;
		phandle = <0x27>;
	};

	audio-amplifier {
		compatible = "simple-audio-amplifier";
		VCC-supply = <0x2b>;
		enable-gpios = <0x23 0x07 0x07 0x00>;
		sound-name-prefix = "Speaker Amp";
		phandle = <0x11>;
	};

	__symbols__ {
		simplefb_lcd = "/chosen/framebuffer-lcd";
		simplefb_hdmi = "/chosen/framebuffer-hdmi";
		cpu0 = "/cpus/cpu@0";
		cpu1 = "/cpus/cpu@1";
		cpu2 = "/cpus/cpu@2";
		cpu3 = "/cpus/cpu@3";
		L2 = "/cpus/l2-cache";
		de = "/display-engine";
		osc24M = "/osc24M_clk";
		osc32k = "/osc32k_clk";
		sound = "/sound";
		cpudai = "/sound/simple-audio-card,cpu";
		link_codec = "/sound/simple-audio-card,codec";
		spdif_out = "/spdif-out";
		display_clocks = "/soc/bus@1000000/clock@0";
		mixer0 = "/soc/bus@1000000/mixer@100000";
		mixer0_out = "/soc/bus@1000000/mixer@100000/ports/port@1";
		mixer0_out_tcon0 = "/soc/bus@1000000/mixer@100000/ports/port@1/endpoint@0";
		mixer0_out_tcon1 = "/soc/bus@1000000/mixer@100000/ports/port@1/endpoint@1";
		mixer1 = "/soc/bus@1000000/mixer@200000";
		mixer1_out = "/soc/bus@1000000/mixer@200000/ports/port@1";
		mixer1_out_tcon0 = "/soc/bus@1000000/mixer@200000/ports/port@1/endpoint@0";
		mixer1_out_tcon1 = "/soc/bus@1000000/mixer@200000/ports/port@1/endpoint@1";
		syscon = "/soc/syscon@1c00000";
		sram_c = "/soc/syscon@1c00000/sram@18000";
		de2_sram = "/soc/syscon@1c00000/sram@18000/sram-section@0";
		sram_c1 = "/soc/syscon@1c00000/sram@1d00000";
		ve_sram = "/soc/syscon@1c00000/sram@1d00000/sram-section@0";
		dma = "/soc/dma-controller@1c02000";
		tcon0 = "/soc/lcd-controller@1c0c000";
		tcon0_in = "/soc/lcd-controller@1c0c000/ports/port@0";
		tcon0_in_mixer0 = "/soc/lcd-controller@1c0c000/ports/port@0/endpoint@0";
		tcon0_in_mixer1 = "/soc/lcd-controller@1c0c000/ports/port@0/endpoint@1";
		tcon0_out = "/soc/lcd-controller@1c0c000/ports/port@1";
		tcon1 = "/soc/lcd-controller@1c0d000";
		tcon1_in = "/soc/lcd-controller@1c0d000/ports/port@0";
		tcon1_in_mixer0 = "/soc/lcd-controller@1c0d000/ports/port@0/endpoint@0";
		tcon1_in_mixer1 = "/soc/lcd-controller@1c0d000/ports/port@0/endpoint@1";
		tcon1_out = "/soc/lcd-controller@1c0d000/ports/port@1";
		tcon1_out_hdmi = "/soc/lcd-controller@1c0d000/ports/port@1/endpoint@1";
		mmc0 = "/soc/mmc@1c0f000";
		mmc1 = "/soc/mmc@1c10000";
		rtl8723cs = "/soc/mmc@1c10000/wifi@1";
		mmc2 = "/soc/mmc@1c11000";
		sid = "/soc/eeprom@1c14000";
		usb_otg = "/soc/usb@1c19000";
		usbphy = "/soc/phy@1c19400";
		ehci0 = "/soc/usb@1c1a000";
		ohci0 = "/soc/usb@1c1a400";
		ehci1 = "/soc/usb@1c1b000";
		ohci1 = "/soc/usb@1c1b400";
		ccu = "/soc/clock@1c20000";
		pio = "/soc/pinctrl@1c20800";
		csi_pins = "/soc/pinctrl@1c20800/csi-pins";
		csi_mclk_pin = "/soc/pinctrl@1c20800/csi-mclk-pin";
		i2c0_pins = "/soc/pinctrl@1c20800/i2c0-pins";
		i2c1_pins = "/soc/pinctrl@1c20800/i2c1-pins";
		lcd_rgb666_pins = "/soc/pinctrl@1c20800/lcd-rgb666-pins";
		mmc0_pins = "/soc/pinctrl@1c20800/mmc0-pins";
		mmc1_pins = "/soc/pinctrl@1c20800/mmc1-pins";
		mmc2_pins = "/soc/pinctrl@1c20800/mmc2-pins";
		mmc2_ds_pin = "/soc/pinctrl@1c20800/mmc2-ds-pin";
		pwm_pin = "/soc/pinctrl@1c20800/pwm-pin";
		rmii_pins = "/soc/pinctrl@1c20800/rmii-pins";
		rgmii_pins = "/soc/pinctrl@1c20800/rgmii-pins";
		spdif_tx_pin = "/soc/pinctrl@1c20800/spdif-tx-pin";
		spi0_pins = "/soc/pinctrl@1c20800/spi0-pins";
		spi1_pins = "/soc/pinctrl@1c20800/spi1-pins";
		uart0_pb_pins = "/soc/pinctrl@1c20800/uart0-pb-pins";
		uart1_pins = "/soc/pinctrl@1c20800/uart1-pins";
		uart1_rts_cts_pins = "/soc/pinctrl@1c20800/uart1-rts-cts-pins";
		uart2_pins = "/soc/pinctrl@1c20800/uart2-pins";
		uart3_pins = "/soc/pinctrl@1c20800/uart3-pins";
		uart4_pins = "/soc/pinctrl@1c20800/uart4-pins";
		uart4_rts_cts_pins = "/soc/pinctrl@1c20800/uart4-rts-cts-pins";
		spdif = "/soc/spdif@1c21000";
		lradc = "/soc/lradc@1c21800";
		i2s0 = "/soc/i2s@1c22000";
		i2s1 = "/soc/i2s@1c22400";
		dai = "/soc/dai@1c22c00";
		codec = "/soc/codec@1c22e00";
		uart0 = "/soc/serial@1c28000";
		uart1 = "/soc/serial@1c28400";
		uart2 = "/soc/serial@1c28800";
		uart3 = "/soc/serial@1c28c00";
		uart4 = "/soc/serial@1c29000";
		i2c0 = "/soc/i2c@1c2ac00";
		i2c1 = "/soc/i2c@1c2b000";
		i2c2 = "/soc/i2c@1c2b400";
		spi0 = "/soc/spi@1c68000";
		spi1 = "/soc/spi@1c69000";
		emac = "/soc/ethernet@1c30000";
		mdio = "/soc/ethernet@1c30000/mdio";
		mali = "/soc/gpu@1c40000";
		gic = "/soc/interrupt-controller@1c81000";
		pwm = "/soc/pwm@1c21400";
		csi = "/soc/csi@1cb0000";
		hdmi = "/soc/hdmi@1ee0000";
		hdmi_in = "/soc/hdmi@1ee0000/ports/port@0";
		hdmi_in_tcon1 = "/soc/hdmi@1ee0000/ports/port@0/endpoint";
		hdmi_out = "/soc/hdmi@1ee0000/ports/port@1";
		hdmi_phy = "/soc/hdmi-phy@1ef0000";
		rtc = "/soc/rtc@1f00000";
		r_intc = "/soc/interrupt-controller@1f00c00";
		r_ccu = "/soc/clock@1f01400";
		codec_analog = "/soc/codec-analog@1f015c0";
		r_i2c = "/soc/i2c@1f02400";
		r_ir = "/soc/ir@1f02000";
		r_pwm = "/soc/pwm@1f03800";
		r_pio = "/soc/pinctrl@1f02c00";
		r_i2c_pl89_pins = "/soc/pinctrl@1f02c00/r-i2c-pl89-pins";
		r_ir_rx_pin = "/soc/pinctrl@1f02c00/r-ir-rx-pin";
		r_pwm_pin = "/soc/pinctrl@1f02c00/r-pwm-pin";
		r_rsb_pins = "/soc/pinctrl@1f02c00/r-rsb-pins";
		r_rsb = "/soc/rsb@1f03400";
		axp803 = "/soc/rsb@1f03400/pmic@3a3";
		ac_power_supply = "/soc/rsb@1f03400/pmic@3a3/ac-power-supply";
		axp_adc = "/soc/rsb@1f03400/pmic@3a3/adc";
		axp_gpio = "/soc/rsb@1f03400/pmic@3a3/gpio";
		gpio0_ldo = "/soc/rsb@1f03400/pmic@3a3/gpio/gpio0-ldo";
		gpio1_ldo = "/soc/rsb@1f03400/pmic@3a3/gpio/gpio1-ldo";
		battery_power_supply = "/soc/rsb@1f03400/pmic@3a3/battery-power-supply";
		reg_aldo1 = "/soc/rsb@1f03400/pmic@3a3/regulators/aldo1";
		reg_aldo2 = "/soc/rsb@1f03400/pmic@3a3/regulators/aldo2";
		reg_aldo3 = "/soc/rsb@1f03400/pmic@3a3/regulators/aldo3";
		reg_dc1sw = "/soc/rsb@1f03400/pmic@3a3/regulators/dc1sw";
		reg_dcdc1 = "/soc/rsb@1f03400/pmic@3a3/regulators/dcdc1";
		reg_dcdc2 = "/soc/rsb@1f03400/pmic@3a3/regulators/dcdc2";
		reg_dcdc3 = "/soc/rsb@1f03400/pmic@3a3/regulators/dcdc3";
		reg_dcdc4 = "/soc/rsb@1f03400/pmic@3a3/regulators/dcdc4";
		reg_dcdc5 = "/soc/rsb@1f03400/pmic@3a3/regulators/dcdc5";
		reg_dcdc6 = "/soc/rsb@1f03400/pmic@3a3/regulators/dcdc6";
		reg_dldo1 = "/soc/rsb@1f03400/pmic@3a3/regulators/dldo1";
		reg_dldo2 = "/soc/rsb@1f03400/pmic@3a3/regulators/dldo2";
		reg_dldo3 = "/soc/rsb@1f03400/pmic@3a3/regulators/dldo3";
		reg_dldo4 = "/soc/rsb@1f03400/pmic@3a3/regulators/dldo4";
		reg_eldo1 = "/soc/rsb@1f03400/pmic@3a3/regulators/eldo1";
		reg_eldo2 = "/soc/rsb@1f03400/pmic@3a3/regulators/eldo2";
		reg_eldo3 = "/soc/rsb@1f03400/pmic@3a3/regulators/eldo3";
		reg_fldo1 = "/soc/rsb@1f03400/pmic@3a3/regulators/fldo1";
		reg_fldo2 = "/soc/rsb@1f03400/pmic@3a3/regulators/fldo2";
		reg_ldo_io0 = "/soc/rsb@1f03400/pmic@3a3/regulators/ldo-io0";
		reg_ldo_io1 = "/soc/rsb@1f03400/pmic@3a3/regulators/ldo-io1";
		reg_rtc_ldo = "/soc/rsb@1f03400/pmic@3a3/regulators/rtc-ldo";
		reg_drivevbus = "/soc/rsb@1f03400/pmic@3a3/regulators/drivevbus";
		usb_power_supply = "/soc/rsb@1f03400/pmic@3a3/usb-power-supply";
		wdt0 = "/soc/watchdog@1c20ca0";
		vdd_bl = "/regulator@0";
		backlight = "/backlight";
		reg_vcc3v3 = "/vcc3v3";
		wifi_pwrseq = "/wifi_pwrseq";
		speaker_amp = "/audio-amplifier";
	};
};
